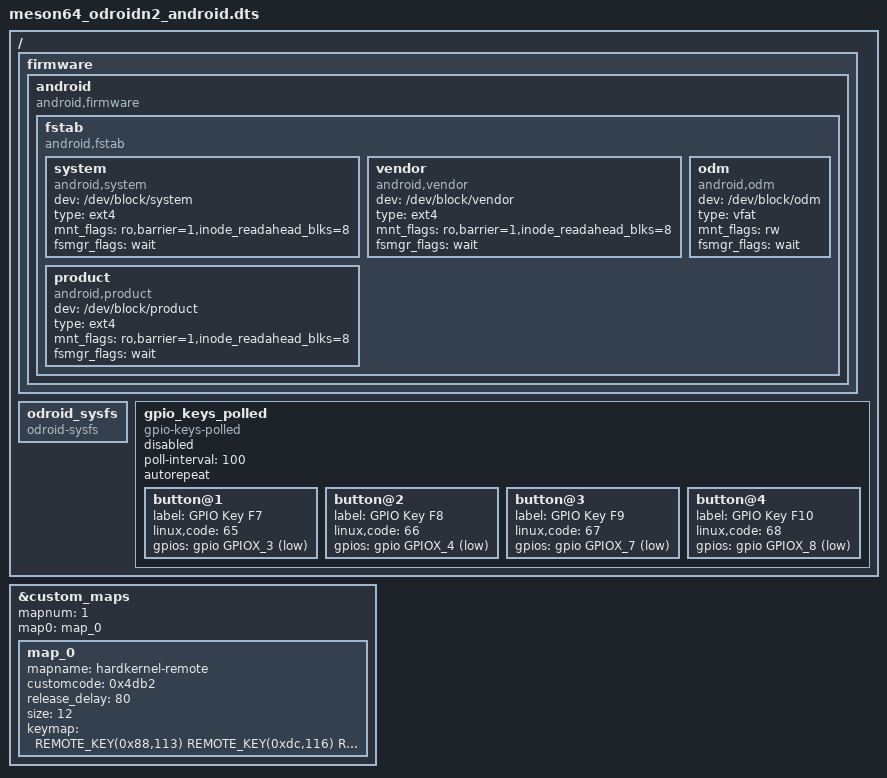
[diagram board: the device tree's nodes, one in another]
/*
 * arch/arm64/boot/dts/amlogic/meson64_odroidc3_android.dts
 *
 * Copyright (C) 2018 Hardkernel Co., Ltd. All rights reserved.
 *
 * This program is free software; you can redistribute it and/or modify
 * it under the terms of the GNU General Public License as published by
 * the Free Software Foundation; either version 2 of the License, or
 * (at your option) any later version.
 *
 * This program is distributed in the hope that it will be useful, but WITHOUT
 * ANY WARRANTY; without even the implied warranty of MERCHANTABILITY or
 * FITNESS FOR A PARTICULAR PURPOSE.  See the GNU General Public License for
 * more details.
 *
 */

#include "meson64_odroidn2.dts"

/ {
	firmware {
		android {
			compatible = "android,firmware";
			fstab {
				compatible = "android,fstab";
				system {
					compatible = "android,system";
					dev = "/dev/block/system";
					type = "ext4";
					mnt_flags = "ro,barrier=1,inode_readahead_blks=8";
					fsmgr_flags = "wait";
				};
				vendor {
					compatible = "android,vendor";
					dev = "/dev/block/vendor";
					type = "ext4";
					mnt_flags = "ro,barrier=1,inode_readahead_blks=8";
					fsmgr_flags = "wait";
				};
				odm {
					compatible = "android,odm";
					dev = "/dev/block/odm";
					type = "vfat";
					mnt_flags = "rw";
					fsmgr_flags = "wait";
				};
				product {
					compatible = "android,product";
					dev = "/dev/block/product";
					type = "ext4";
					mnt_flags = "ro,barrier=1,inode_readahead_blks=8";
					fsmgr_flags = "wait";
				};
			};
		};
	};

	odroid_sysfs {
		compatible = "odroid-sysfs";
		status = "okay";
	};

	gpio_keys_polled {
		status = "disabled";
		compatible =
			"gpio-keys-polled";
			#address-cells = <1>;
			#size-cells = <0>;
			poll-interval = <100>;
			autorepeat;
			button@1 {
				label = "GPIO Key F7";
				linux,code = <65>;
				gpios = <&gpio GPIOX_3 1>;
			};
			button@2 {
				label = "GPIO Key F8";
				linux,code = <66>;
				gpios = <&gpio GPIOX_4 1>;
			};
			button@3 {
				label = "GPIO Key F9";
				linux,code = <67>;
				gpios = <&gpio GPIOX_7 1>;
			};
			button@4 {
				label = "GPIO Key F10";
				linux,code = <68>;
				gpios = <&gpio GPIOX_8 1>;
			};
	};
};

&custom_maps {
	mapnum = <1>;
	map0 = <&map_0>;
	map_0: map_0 {
		mapname = "hardkernel-remote";
		customcode = <0x4db2>;
		release_delay = <80>;
		size  = <12>;
		keymap = <REMOTE_KEY(0x88,113)
			REMOTE_KEY(0xdc,116)
			REMOTE_KEY(0xc5,139)
			REMOTE_KEY(0x9a,158)
			REMOTE_KEY(0xca,103)
			REMOTE_KEY(0x99,105)
			REMOTE_KEY(0xc1,106)
			REMOTE_KEY(0xd2,108)
			REMOTE_KEY(0x80,104)
			REMOTE_KEY(0x81,109)
			REMOTE_KEY(0x82,102)
			REMOTE_KEY(0xce,97)>;
	};
};
